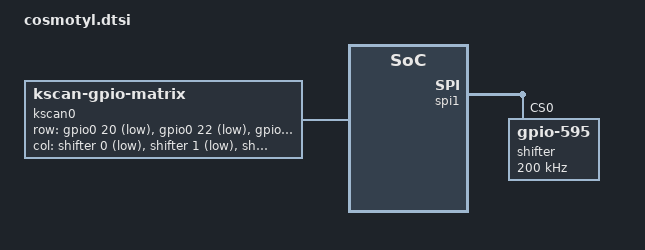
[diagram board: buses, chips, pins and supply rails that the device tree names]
#include <behaviors.dtsi>
#include <dt-bindings/zmk/matrix_transform.h>
#include <dt-bindings/zmk/keys.h>

// Tell VIK that there is 1 other device on the SPI bus.
// You will need to increase this number if you add another SPI device.
#define VIK_SPI_REG_START 1
// Pulled out to an external variable so VIK can find the SPI bus.
#define VIK_SPI_CS_PREFIX <&gpio0 4 GPIO_ACTIVE_LOW>

&spi1 {
    status = "okay";
    cs-gpios = VIK_SPI_CS_PREFIX;

    shifter: 595@0 {
        compatible = "zmk,gpio-595";
        status = "okay";
        gpio-controller;
        spi-max-frequency = <200000>;
        reg = <0>;
        ngpios = <8>;
        #gpio-cells = <2>;
    };
};

/ {
    chosen {
        zmk,kscan = &kscan0;
        zmk,matrix_transform = &default_transform;
    };

    default_transform: keymap_transform_0 {
        compatible = "zmk,matrix-transform";
        columns = <14>;
        rows = <7>;
        map = <RC(1,0) RC(2,1) RC(3,2) RC(3,3) RC(2,4) RC(2,5) RC(2,0) RC(2,1) RC(3,2) RC(3,3) RC(2,4) RC(1,5) RC(0,0) RC(1,1) RC(2,2) RC(2,3) RC(1,4) RC(1,5) RC(1,0) RC(1,1) RC(2,2) RC(2,3) RC(1,4) RC(0,5) RC(0,1) RC(1,2) RC(0,3) RC(0,4) RC(0,5) RC(0,0) RC(0,1) RC(1,2) RC(1,3) RC(0,4) RC(0,1) RC(0,2) RC(0,2) RC(0,3) RC(6,4) RC(6,2) RC(6,0) RC(6,3) RC(6,4) RC(6,5) RC(6,5) RC(6,3) RC(6,1) RC(6,2) RC(6,1) RC(6,0)>;
    };

    kscan0: kscan_0 {
        compatible = "zmk,kscan-gpio-matrix";

        diode-direction = "col2row";
        row-gpios
            = <&gpio0 20 (GPIO_ACTIVE_LOW | GPIO_PULL_UP)>
            , <&gpio0 22 (GPIO_ACTIVE_LOW | GPIO_PULL_UP)>
            , <&gpio0 24 (GPIO_ACTIVE_LOW | GPIO_PULL_UP)>
            , <&gpio0 9  (GPIO_ACTIVE_LOW | GPIO_PULL_UP)>
            , <&gpio0 10 (GPIO_ACTIVE_LOW | GPIO_PULL_UP)>
            , <&gpio1 13 (GPIO_ACTIVE_LOW | GPIO_PULL_UP)>
            , <&gpio1 15 (GPIO_ACTIVE_LOW | GPIO_PULL_UP)>
            ;

        col-gpios
            = <&shifter 0 GPIO_ACTIVE_LOW>
            , <&shifter 1 GPIO_ACTIVE_LOW>
            , <&shifter 2 GPIO_ACTIVE_LOW>
            , <&shifter 3 GPIO_ACTIVE_LOW>
            , <&shifter 4 GPIO_ACTIVE_LOW>
            , <&shifter 5 GPIO_ACTIVE_LOW>
            , <&shifter 6 GPIO_ACTIVE_LOW>
            ;
    };
};
